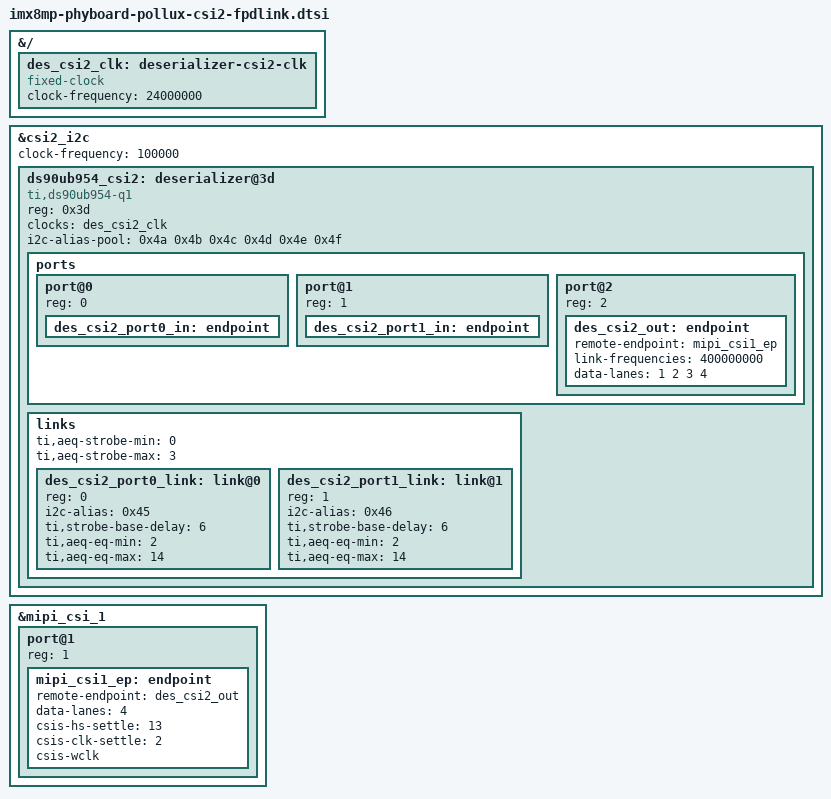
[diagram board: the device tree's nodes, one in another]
// SPDX-License-Identifier: (GPL-2.0+ OR MIT)
/*
 * Copyright (C) 2022 PHYTEC Messtechnik GmbH
 * Author: Stefan Riedmueller <s.riedmueller@phytec.de>
 */

/dts-v1/;
/plugin/;

&{/} {
	des_csi2_clk: deserializer-csi2-clk {
		#clock-cells = <0>;
		compatible = "fixed-clock";
		clock-frequency = <24000000>;
	};
};

&csi2_i2c {
	#address-cells = <1>;
	#size-cells = <0>;

	clock-frequency = <100000>;
	status = "okay";

	ds90ub954_csi2: deserializer@3d {
		compatible = "ti,ds90ub954-q1";
		reg = <0x3d>;

		clocks = <&des_csi2_clk>;
		clock-names = "refclk";

		i2c-alias-pool = <0x4a 0x4b 0x4c 0x4d 0x4e 0x4f>;

		ports {
			#address-cells = <0x1>;
			#size-cells = <0x0>;
			port@0 {
				reg = <0>;
				des_csi2_port0_in: endpoint {};
			};

			port@1 {
				reg = <1>;
				des_csi2_port1_in: endpoint {};
			};

			port@2 {
				reg = <2>;
				des_csi2_out: endpoint {
					remote-endpoint = <&mipi_csi1_ep>;
					link-frequencies = /bits/ 64 <
						400000000
					>;
					data-lanes = <1 2 3 4>;
				};
			};
		};

		links {
			#address-cells = <1>;
			#size-cells = <0>;

			ti,aeq-strobe-min = <0>;
			ti,aeq-strobe-max = <3>;

			des_csi2_port0_link: link@0 {
				reg = <0>;
				i2c-alias = <0x45>;

				ti,strobe-base-delay = <6>;
				ti,aeq-eq-min = <2>;
				ti,aeq-eq-max = <14>;
			};

			des_csi2_port1_link: link@1 {
				reg = <1>;
				i2c-alias = <0x46>;

				ti,strobe-base-delay = <6>;
				ti,aeq-eq-min = <2>;
				ti,aeq-eq-max = <14>;
			};

		};
	};
};

&mipi_csi_1 {
	#address-cells = <1>;
	#size-cells = <0>;

	port@1 {
		reg = <1>;
		mipi_csi1_ep: endpoint {
			remote-endpoint = <&des_csi2_out>;
			data-lanes = <4>;
			csis-hs-settle = <13>;
			csis-clk-settle = <2>;
			csis-wclk;
		};
	};
};
